# K1921VK028 register map
Vendor: NIIET; Series: K1921VKx; File version: 2.17
CPU: CM4 r0p1, little endian, MPU, FPU, 4 interrupt priority bits
Registers are 32-bit, read-write, reset 0x0 unless marked. A register's access mark holds for its fields unless they carry their own. Offsets are from the block's base; [hi:lo] are bit positions; lines under a group give offsets from that group; {n}, {i} and the like mark numbered series.

## ECAP0 — ECAP controller registers
Base 0x4009A000
Same registers: ECAP1 0x4009B000, ECAP2 0x4009C000, ECAP3 0x4009D000, ECAP4 0x4009E000, ECAP5 0x4009F000
0x00 TSCTR — Counter register
  [31:0] VAL
0x04 CTRPHS — Counter Phase Sync register
  [31:0] VAL
{0x8+4i} CAP{i} (i=0..3) — Capture register {i}
  [31:0] VAL
0x08 PRD (alternate view of CAP0) — Period register
  [31:0] VAL — Period value in APWM mode
0x0C CMP (alternate view of CAP1) — Compare register
  [31:0] VAL — Compare value in APWM mode
0x10 PRDSHDW (alternate view of CAP2) — Period shadow register
  [31:0] VAL — Period shadow value in APWM mode
0x14 CMPSHDW (alternate view of CAP3) — Compare shadow register
  [31:0] VAL — Compare shadow value in APWM mode
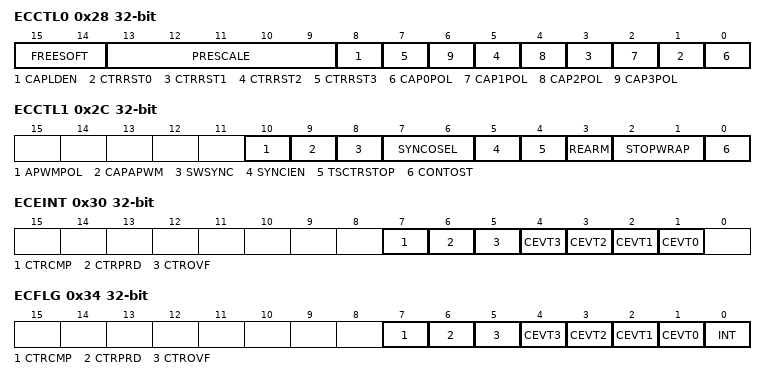
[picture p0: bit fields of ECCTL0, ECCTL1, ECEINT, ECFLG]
0x28 ECCTL0 — Capture control register 0
  [15:14] FREESOFT
    0=stop timer immedeatelly; 1=StopAtZero (stop timer when reach zero); 2=Free (normal work)
  [13:9] PRESCALE
  [8] CAPLDEN — enable capture
  [2n+1] CTRRST{n} (n=0..3) — Reset counter after event {n}
  [2n] CAP{n}POL (n=0..3) — Polarity select for capture {n}
0x2C ECCTL1 — Capture control register 1
  [10] APWMPOL — High/low level APWM
  [9] CAPAPWM — Capture mode or APWM mode
  [8] SWSYNC — Software timers sync
  [7:6] SYNCOSEL
    0=Bypass (sync in connected with sync out); 1=CTREqPrd (sync out generated when CTR = PRD); 2=Disable (sync out generate disabled)
  [5] SYNCIEN — Sync in enable
  [4] TSCTRSTOP — Enable Timer
  [3] REARM — Reset and enable controller, capture reg load
  [2:1] STOPWRAP
  [0] CONTOST — Capture mode
0x30 ECEINT — Interrupt mask register
  [7] CTRCMP — enable int CTR=CMP
  [6] CTRPRD — enable int CTR=PRD
  [5] CTROVF — enable int CTR_OVF
  [n+1] CEVT{n} (n=0..3) — enable int CEVT{n}
0x34 ECFLG ro — Interrupt status register
  [7] CTRCMP — Hap interrupt CTR=CMP
  [6] CTRPRD — Hap interrupt CTR=PRD
  [5] CTROVF — Hap interrupt CTROVF
  [n+1] CEVT{n} (n=0..3) — Hap interrupt CEVT{n}
  [0] INT — indicate global interrupt
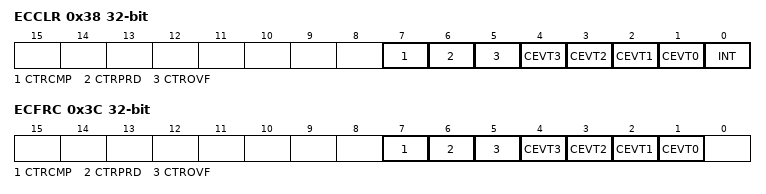
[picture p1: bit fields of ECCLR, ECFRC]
0x38 ECCLR wo — Clear interrupt register
  [7] CTRCMP — reset intstatus
  [6] CTRPRD — reset intstatus
  [5] CTROVF — reset intstatus
  [n+1] CEVT{n} (n=0..3) — reset intstatus
  [0] INT — reset global interrupt
0x3C ECFRC wo — Force interrupt register
  [7] CTRCMP — gen test interrupt
  [6] CTRPRD — gen test interrupt
  [5] CTROVF — gen test interrupt
  [n+1] CEVT{n} (n=0..3) — gen test interrupt
0x40 PEINT — Active interrupt status register
  [0] PEINT — active interrupt flag

## SPWRTMR — SpaceWire timer controller registers
Base 0x40074000
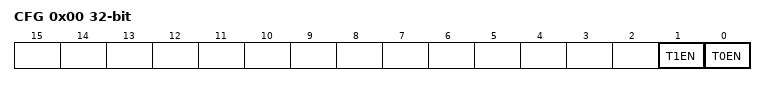
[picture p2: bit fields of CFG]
0x00 CFG — SpaceWire Tick Control Register
  [1] T1EN — Enable timer 1 count
  [0] T0EN — Enable timer 0 count
0x04 REL0 — SpaceWire Timer 0 Reload value register
  [31:0] VAL — Timer 0 Reload value
0x08 REL1 — SpaceWire Timer 1 Reload value register
  [31:0] VAL — Timer 1 Reload value

## SPWR0 — SpaceWire control registers
Base 0x40070000
Same registers: SPWR1 0x40071000
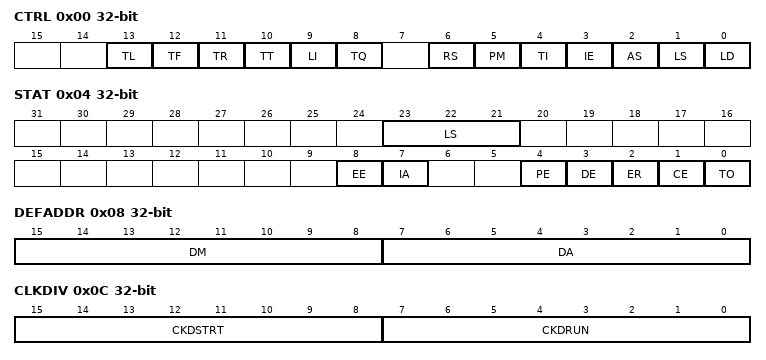
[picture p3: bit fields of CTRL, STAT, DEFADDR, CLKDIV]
0x00 CTRL — Control Register
  [13] TL — Transmitter enable lock control
  [12] TF — Time_coded control flag filter
  [11] TR — Time RX enable
  [10] TT — Time TX enable
  [9] LI — Link Error IRQ
  [8] TQ — Tick-out IRQ
  [6] RS — Reset
  [5] PM — Promiscious Mode
  [4] TI — Tick In
  [3] IE — Interrupt Enable
  [2] AS — Link Autostart
  [1] LS — Link Start
  [0] LD — Link Disable
0x04 STAT — Status Register
  [23:21] LS — Link State
    0=error reset state; 1=error wait state; 2=ready state; 3=started state; 4=connecting state; 5=Run (run state)
  [8] EE — Early EOP/EEP received
  [7] IA — Invalid Address
  [4] PE — Parity Error
  [3] DE — Disconnect Error
  [2] ER — Escape Error
  [1] CE — Credit Error
  [0] TO — New Timecount value was received
0x08 DEFADDR — Default Address Register
  [15:8] DM — Default address mask
  [7:0] DA — Default Address
0x0C CLKDIV — Clock Divisor Register
  [15:8] CKDSTRT — Clock Divisor in startup
  [7:0] CKDRUN — Clock Divisor In Run State
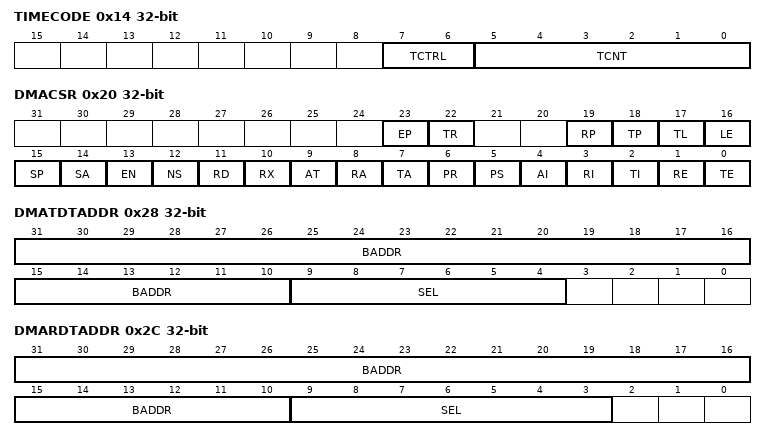
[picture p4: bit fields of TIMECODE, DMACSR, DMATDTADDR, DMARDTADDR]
0x14 TIMECODE
  [7:6] TCTRL — Time Control Flags
  [5:0] TCNT — Time Counter Value
0x20 DMACSR — DMA Control/Status Register
  [23] EP — EEP Termination
  [22] TR — Truncated
  [19] RP — Receive packet IRQ
  [18] TP — Transmit packet IRQ
  [17] TL — Transmiter Enable Lock
  [16] LE — Link Error Disable transmitter
  [15] SP — Strip PID
  [14] SA — Strip Address
  [13] EN — Enable Address
  [12] NS — No Spills
  [11] RD — RX descriptors Available
  [10] RX ro — RX Active
  [9] AT — Abort Tx
  [8] RA — RX AHB Error
  [7] TA — TX AHB Error
  [6] PR — Packet Received
  [5] PS — Packet Sent
  [4] AI — AHB Error Interrupt
  [3] RI — Receive Interrupt
  [2] TI — Transmit Interrupt
  [1] RE — Receiver Rnable
  [0] TE — Transmitter Enable
0x24 DMARXLEN — DMA RX Maximum Length Register
  [24:0] RXMAXLEN ro — RX maximum length packet value
0x28 DMATDTADDR — DMA Transmit Descriptor Table Address Register
  [31:10] BADDR — Descriptor Table Base Address
  [9:4] SEL — Descriptor Selector
0x2C DMARDTADDR — DMA Receive Descriptor Table Address Register
  [31:10] BADDR — Descriptor Table Base Address
  [9:3] SEL — Descriptor Selector
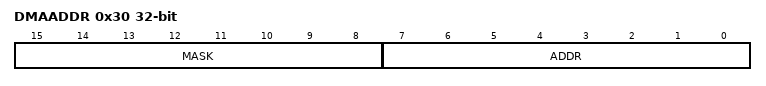
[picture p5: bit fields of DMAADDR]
0x30 DMAADDR
  [15:8] MASK — Mask value for node Identification
  [7:0] ADDR — Address Value For Node Identification

## RTC — RTC controller registers
Base 0x40099000
0x00 POS — Parts of seconds register
  [9:0] VAL — Parts of seconds
0x04 SEC — Second register
  [6:0] VAL — Seconds in BCD format
0x08 MIN — Minute register
  [6:0] VAL — Minutes in BCD format
0x10 HOUR
  [5:0] VAL — Hours in BCD format
0x18 DOW — Day of week register
  [2:0] VAL
0x20 DAY
  [5:0] VAL — Day in BCD format
0x24 MONTH
  [4:0] VAL — Month in BCD format
0x28 YEAR
  [7:0] VAL — Year in BCD format
0x2C SHDW wo — Register Update shadow registers RTC
  [7] UPDTEN — Enable update shadow registers RTC
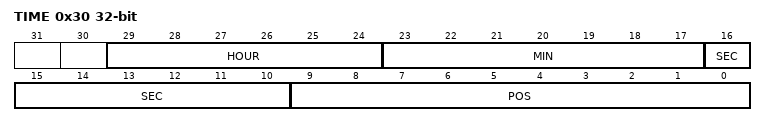
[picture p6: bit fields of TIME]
0x30 TIME ro — General register Time
  [29:24] HOUR — Hours
  [23:17] MIN — Minutes
  [16:10] SEC — Seconds
  [9:0] POS — Parts of seconds

## LAU — LAU controller registers
Base 0x400AE000
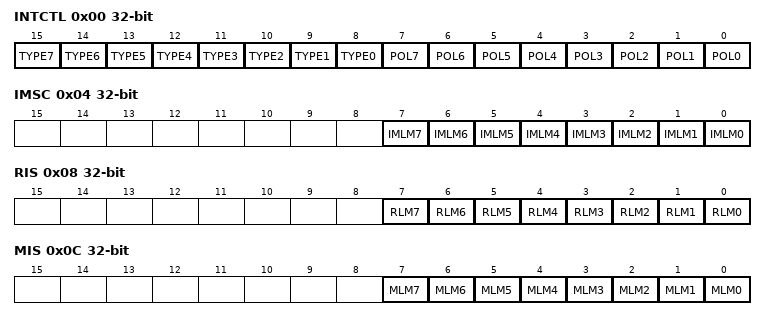
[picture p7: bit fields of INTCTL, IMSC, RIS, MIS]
0x00 INTCTL — Interrupt control register
  [n+8] TYPE{n} (n=0..7) — Interrupt type select for LM{n}
  [n] POL{n} (n=0..7) — Interrupt polarity select for LM{n}
0x04 IMSC — Interrupt Mask Set/Clear Register
  [n] IMLM{n} (n=0..7) — LM{n} interrupt mask
0x08 RIS ro — Raw Interrupt Status Register
  [n] RLM{n} (n=0..7) — LM{n} interrupt status
0x0C MIS ro — Masked Interrupt Status Register
  [n] MLM{n} (n=0..7) — LM{n} masked interrupt status
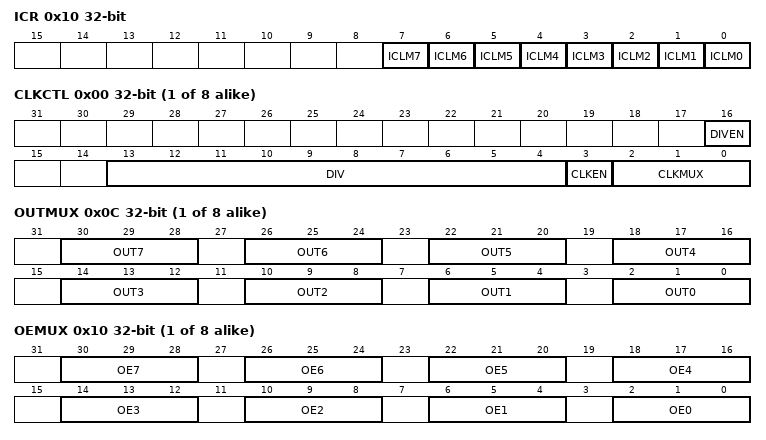
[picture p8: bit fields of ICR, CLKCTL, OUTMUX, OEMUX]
0x10 ICR wo — Interrupt Clear Register
  [n] ICLM{n} (n=0..7) — LM{n} interrupt clear
{0x20+0x78*i} LM[{i}] (i=0..7) group
  0x00 CLKCTL — Clock Control Register
    [16] DIVEN — Clock divider enable
    [13:4] DIV — Clock divider
    [3] CLKEN — Clock enable
    [2:0] CLKMUX — Clock select
  0x04 INTSEL — Interrupt Selection Register
    [2:0] LUTNUM — LUT chanel to make interrupt
  0x08 BUSSEL — LM_BUS Signal Selection Register
    [2:0] LMNUM — LUT chanel out to LMBUS
  0x0C OUTMUX — LM_OUT Selection Register
    [4n+2:4n] OUT{n} (n=0..7) — LUT chanel connected to OUT_{n}
  0x10 OEMUX — LM_OE Selection Register
    [4n+2:4n] OE{n} (n=0..7) — LUT chanel connected to OE_{n}
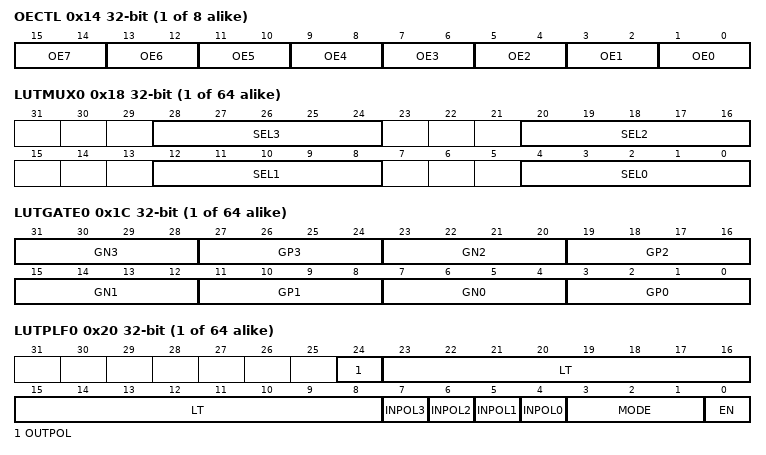
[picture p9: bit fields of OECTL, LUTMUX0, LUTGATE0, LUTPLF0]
  0x14 OECTL — LM_OE Control Register
    [2n+1:2n] OE{n} (n=0..7) — Type of OE{n}
  {0x18+0xC*j} LUTMUX{j} (j=0..7) — LUT{j} Input Multiplexor Register
    [8n+4:8n] SEL{n} (n=0..3) — Input select for Gate{n}
  {0x1C+0xC*j} LUTGATE{j} (j=0..7) — LUT{j} Gate Config Register
    [8n+7:8n+4] GN{n} (n=0..3) — Gate {n} negative signal enable
    [8n+3:8n] GP{n} (n=0..3) — Gate {n} positive signal enable
  {0x20+0xC*j} LUTPLF{j} (j=0..7) — LUT{j} PLF Config Register
    [24] OUTPOL — Output signal inverce
    [23:8] LT — Logic Table bit 0
    [n+4] INPOL{n} (n=0..3) — Input signal inverce
    [3:1] MODE — Logical function select
    [0] EN — Enable LUT
